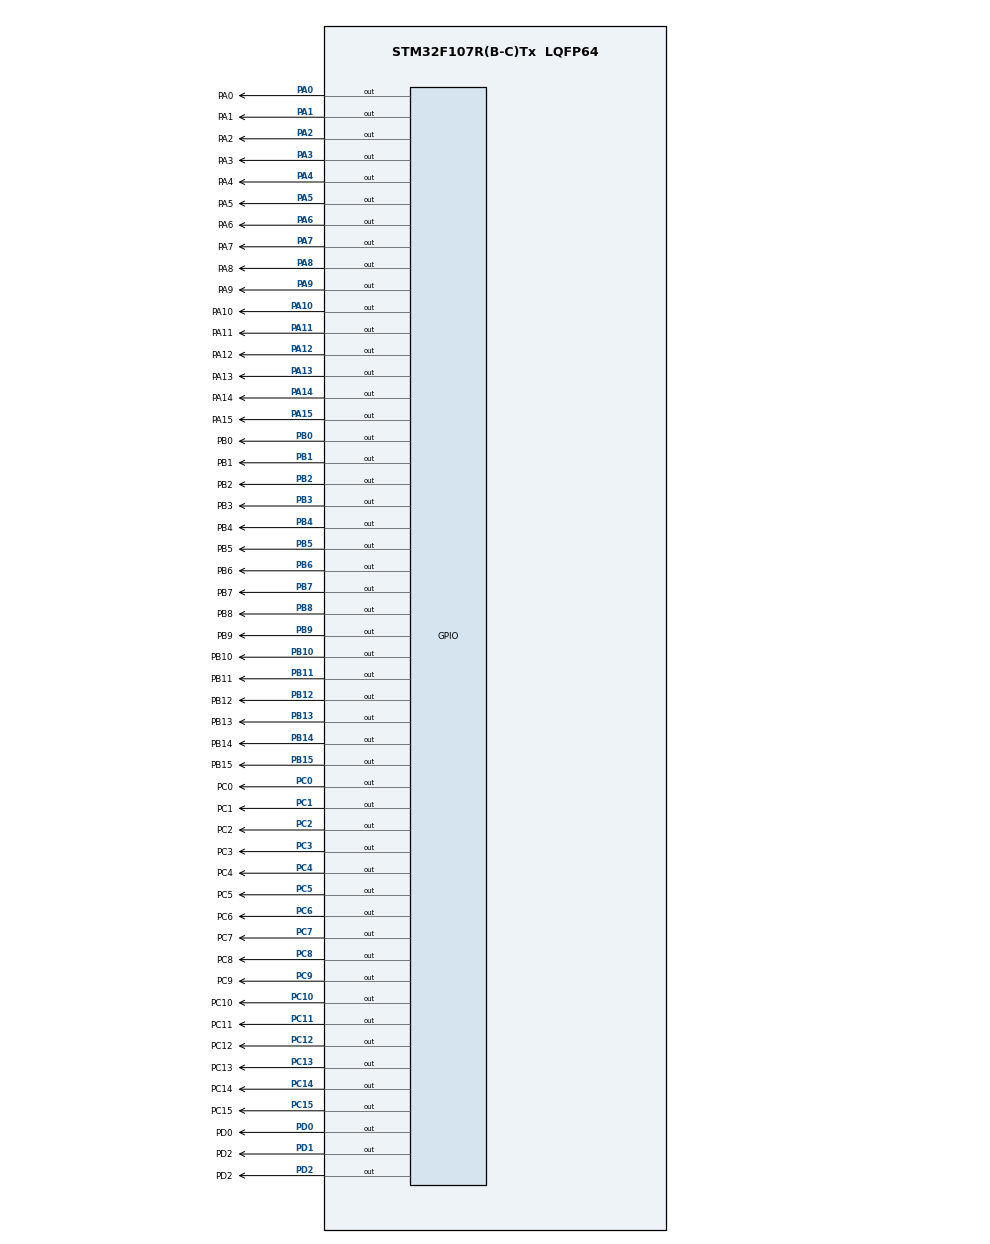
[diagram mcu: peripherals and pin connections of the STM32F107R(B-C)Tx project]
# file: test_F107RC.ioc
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Mcu.Family=STM32F1
PC10.Signal=GPIO_Output
PC12.Signal=GPIO_Output
PB14.GPIO_Label=PB14
PA14.GPIO_Label=PA14
PC0.GPIO_Label=PC0
PC6.GPIO_Label=PC6
PA6.GPIO_Label=PA6
PB0.GPIO_Label=PB0
PB6.GPIO_Label=PB6
PB13.GPIO_Label=PB13
PB11.Signal=GPIO_Output
PB13.Signal=GPIO_Output
PB15.Signal=GPIO_Output
PC15-OSC32_OUT.GPIO_Label=PC15
ProjectManager.StackSize=0x400
PD1-OSC_OUT.Signal=GPIO_Output
PA15.GPIO_Label=PA15
PD1-OSC_OUT.GPIO_Label=PD2
PA12.Signal=GPIO_Output
PB6.Signal=GPIO_Output
PC7.Signal=GPIO_Output
PC3.Signal=GPIO_Output
RCC.MSICalibrationValue=0
PB2.Signal=GPIO_Output
PB12.GPIO_Label=PB12
PC4.GPIO_Label=PC4
PB1.GPIO_Label=PB1
PC11.GPIO_Label=PC11
PA10.GPIO_Label=PA10
PB7.Signal=GPIO_Output
PA8.Signal=GPIO_Output
PB7.GPIO_Label=PB7
Mcu.Package=LQFP64
PB9.Signal=GPIO_Output
PB1.Signal=GPIO_Output
PA6.Signal=GPIO_Output
PA2.GPIO_Label=PA2
PA10.Signal=GPIO_Output
PA15.Signal=GPIO_Output
PB5.GPIO_Label=PB5
PC14-OSC32_IN.GPIO_Label=PC14
PC5.Signal=GPIO_Output
RCC.MSIAutoCalibration=DISABLED
PA4.GPIO_Label=PA4
PC2.GPIO_Label=PC2
PB4.Signal=GPIO_Output
PA3.Signal=GPIO_Output
PB3.GPIO_Label=PB3
PB9.GPIO_Label=PB9
PC10.GPIO_Label=PC10
PC9.GPIO_Label=PC9
PA9.GPIO_Label=PA9
PC11.Signal=GPIO_Output
PC8.Signal=GPIO_Output
PC2.Signal=GPIO_Output
PC4.Signal=GPIO_Output
PC6.Signal=GPIO_Output
PB11.GPIO_Label=PB11
PC13-TAMPER-RTC.Signal=GPIO_Output
PA11.GPIO_Label=PA11
PD0-OSC_IN.Signal=GPIO_Output
PC0.Signal=GPIO_Output
PC14-OSC32_IN.Signal=GPIO_Output
VP_SYS_VS_ND.Mode=No_Debug
PA12.GPIO_Label=PA12
RCC.PWR_Regulator_Voltage_Scale=PWR_REGULATOR_VOLTAGE_SCALE1
PA0-WKUP.GPIO_Label=PA0
PA0-WKUP.Signal=GPIO_Output
PC8.GPIO_Label=PC8
PA13.Signal=GPIO_Output
PB8.GPIO_Label=PB8
PA8.GPIO_Label=PA8
ProjectManager.TargetToolchain=STM32CubeIDE
PB10.GPIO_Label=PB10
PA9.Signal=GPIO_Output
RCC.USBFreq_Value=10666666.666666666
PC15-OSC32_OUT.Signal=GPIO_Output
PA1.Signal=GPIO_Output
PB10.Signal=GPIO_Output
PB14.Signal=GPIO_Output
PA5.Signal=GPIO_Output
board=custom
PD0-OSC_IN.GPIO_Label=PD0
PC13-TAMPER-RTC.GPIO_Label=PC13
PB4.GPIO_Label=PB4
PB15.GPIO_Label=PB15
PA1.GPIO_Label=PA1
PC1.GPIO_Label=PC1
Mcu.Name=STM32F107R(B-C)Tx
PA2.Signal=GPIO_Output
PA13.GPIO_Label=PA13
PC7.GPIO_Label=PC7
PB3.Signal=GPIO_Output
PA4.Signal=GPIO_Output
PB5.Signal=GPIO_Output
PA7.GPIO_Label=PA7
PA5.GPIO_Label=PA5
PC5.GPIO_Label=PC5
PC12.GPIO_Label=PC12
PA11.Signal=GPIO_Output
PA14.Signal=GPIO_Output
PB2.GPIO_Label=PB2
ProjectManager.HeapSize=0x200
NVIC.PriorityGroup=NVIC_PRIORITYGROUP_4
PB8.Signal=GPIO_Output
PC3.GPIO_Label=PC3
PC9.Signal=GPIO_Output
PD2.Signal=GPIO_Output
PB0.Signal=GPIO_Output
PC1.Signal=GPIO_Output
PB12.Signal=GPIO_Output
PD2.GPIO_Label=PD2
PA3.GPIO_Label=PA3
PA7.Signal=GPIO_Output

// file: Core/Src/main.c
/* USER CODE BEGIN Header */
/**
  ******************************************************************************
  * @file           : main.c
  * @brief          : Main program body
  ******************************************************************************
  * @attention
  *
  * <h2><center>&copy; Copyright (c) 2021 STMicroelectronics.
  * All rights reserved.</center></h2>
  *
  * This software component is licensed by ST under BSD 3-Clause license,
  * the "License"; You may not use this file except in compliance with the
  * License. You may obtain a copy of the License at:
  *                        opensource.org/licenses/BSD-3-Clause
  *
  ******************************************************************************
  */
/* USER CODE END Header */
#include "main.h"

/* USER CODE BEGIN Includes */
#include "gpio_ex.h"
/* USER CODE END Includes */

void SystemClock_Config(void);
static void MX_GPIO_Init(void);

int main(void)
{

  /* MCU Configuration--------------------------------------------------------*/

  /* Reset of all peripherals, Initializes the Flash interface and the Systick. */
  HAL_Init();

  /* Configure the system clock */
  SystemClock_Config();

  /* Initialize all configured peripherals */
  MX_GPIO_Init();

  /* Infinite loop */
  /* USER CODE BEGIN WHILE */
  uint16_t i = 0;
  while (1) {
    /* USER CODE END WHILE */
    HAL_GPIO_SetWord(GPIOA, i);
    HAL_GPIO_SetWord(GPIOB, i);
    HAL_GPIO_SetWord(GPIOC, i);
    HAL_GPIO_SetWord(GPIOD, i & 0x07);
    ++i;
  }
}

void SystemClock_Config(void)
{
  RCC_OscInitTypeDef RCC_OscInitStruct = {0};
  RCC_ClkInitTypeDef RCC_ClkInitStruct = {0};

  /** Initializes the RCC Oscillators according to the specified parameters
  * in the RCC_OscInitTypeDef structure.
  */
  RCC_OscInitStruct.OscillatorType = RCC_OSCILLATORTYPE_HSI;
  RCC_OscInitStruct.HSIState = RCC_HSI_ON;
  RCC_OscInitStruct.HSICalibrationValue = RCC_HSICALIBRATION_DEFAULT;
  RCC_OscInitStruct.PLL.PLLState = RCC_PLL_NONE;
  RCC_OscInitStruct.PLL2.PLL2State = RCC_PLL_NONE;
  if (HAL_RCC_OscConfig(&RCC_OscInitStruct) != HAL_OK)
  {
    Error_Handler();
  }
  /** Initializes the CPU, AHB and APB buses clocks
  */
  RCC_ClkInitStruct.ClockType = RCC_CLOCKTYPE_HCLK|RCC_CLOCKTYPE_SYSCLK
                              |RCC_CLOCKTYPE_PCLK1|RCC_CLOCKTYPE_PCLK2;
  RCC_ClkInitStruct.SYSCLKSource = RCC_SYSCLKSOURCE_HSI;
  RCC_ClkInitStruct.AHBCLKDivider = RCC_SYSCLK_DIV1;
  RCC_ClkInitStruct.APB1CLKDivider = RCC_HCLK_DIV1;
  RCC_ClkInitStruct.APB2CLKDivider = RCC_HCLK_DIV1;

  if (HAL_RCC_ClockConfig(&RCC_ClkInitStruct, FLASH_LATENCY_0) != HAL_OK)
  {
    Error_Handler();
  }
  /** Configure the Systick interrupt time
  */
  __HAL_RCC_PLLI2S_ENABLE();
}

static void MX_GPIO_Init(void)
{
  GPIO_InitTypeDef GPIO_InitStruct = {0};

  /* GPIO Ports Clock Enable */
  __HAL_RCC_GPIOC_CLK_ENABLE();
  __HAL_RCC_GPIOD_CLK_ENABLE();
  __HAL_RCC_GPIOA_CLK_ENABLE();
  __HAL_RCC_GPIOB_CLK_ENABLE();

  /*Configure GPIO pin Output Level */
  HAL_GPIO_WritePin(GPIOC, PC13_Pin|PC14_Pin|PC15_Pin|PC0_Pin
                          |PC1_Pin|PC2_Pin|PC3_Pin|PC4_Pin
                          |PC5_Pin|PC6_Pin|PC7_Pin|PC8_Pin
                          |PC9_Pin|PC10_Pin|PC11_Pin|PC12_Pin, GPIO_PIN_RESET);

  /*Configure GPIO pin Output Level */
  HAL_GPIO_WritePin(GPIOD, PD0_Pin|PD2_Pin|PD2D2_Pin, GPIO_PIN_RESET);

  /*Configure GPIO pin Output Level */
  HAL_GPIO_WritePin(GPIOA, PA0_Pin|PA1_Pin|PA2_Pin|PA3_Pin
                          |PA4_Pin|PA5_Pin|PA6_Pin|PA7_Pin
                          |PA8_Pin|PA9_Pin|PA10_Pin|PA11_Pin
                          |PA12_Pin|PA13_Pin|PA14_Pin|PA15_Pin, GPIO_PIN_RESET);

  /*Configure GPIO pin Output Level */
  HAL_GPIO_WritePin(GPIOB, PB0_Pin|PB1_Pin|PB2_Pin|PB10_Pin
                          |PB11_Pin|PB12_Pin|PB13_Pin|PB14_Pin
                          |PB15_Pin|PB3_Pin|PB4_Pin|PB5_Pin
                          |PB6_Pin|PB7_Pin|PB8_Pin|PB9_Pin, GPIO_PIN_RESET);

  /*Configure GPIO pins : PC13_Pin PC14_Pin PC15_Pin PC0_Pin
                           PC1_Pin PC2_Pin PC3_Pin PC4_Pin
                           PC5_Pin PC6_Pin PC7_Pin PC8_Pin
                           PC9_Pin PC10_Pin PC11_Pin PC12_Pin */
  GPIO_InitStruct.Pin = PC13_Pin|PC14_Pin|PC15_Pin|PC0_Pin
                          |PC1_Pin|PC2_Pin|PC3_Pin|PC4_Pin
                          |PC5_Pin|PC6_Pin|PC7_Pin|PC8_Pin
                          |PC9_Pin|PC10_Pin|PC11_Pin|PC12_Pin;
  GPIO_InitStruct.Mode = GPIO_MODE_OUTPUT_PP;
  GPIO_InitStruct.Pull = GPIO_NOPULL;
  GPIO_InitStruct.Speed = GPIO_SPEED_FREQ_LOW;
  HAL_GPIO_Init(GPIOC, &GPIO_InitStruct);

  /*Configure GPIO pins : PD0_Pin PD2_Pin PD2D2_Pin */
  GPIO_InitStruct.Pin = PD0_Pin|PD2_Pin|PD2D2_Pin;
  GPIO_InitStruct.Mode = GPIO_MODE_OUTPUT_PP;
  GPIO_InitStruct.Pull = GPIO_NOPULL;
  GPIO_InitStruct.Speed = GPIO_SPEED_FREQ_LOW;
  HAL_GPIO_Init(GPIOD, &GPIO_InitStruct);

  /*Configure GPIO pins : PA0_Pin PA1_Pin PA2_Pin PA3_Pin
                           PA4_Pin PA5_Pin PA6_Pin PA7_Pin
                           PA8_Pin PA9_Pin PA10_Pin PA11_Pin
                           PA12_Pin PA13_Pin PA14_Pin PA15_Pin */
  GPIO_InitStruct.Pin = PA0_Pin|PA1_Pin|PA2_Pin|PA3_Pin
                          |PA4_Pin|PA5_Pin|PA6_Pin|PA7_Pin
                          |PA8_Pin|PA9_Pin|PA10_Pin|PA11_Pin
                          |PA12_Pin|PA13_Pin|PA14_Pin|PA15_Pin;
  GPIO_InitStruct.Mode = GPIO_MODE_OUTPUT_PP;
  GPIO_InitStruct.Pull = GPIO_NOPULL;
  GPIO_InitStruct.Speed = GPIO_SPEED_FREQ_LOW;
  HAL_GPIO_Init(GPIOA, &GPIO_InitStruct);

  /*Configure GPIO pins : PB0_Pin PB1_Pin PB2_Pin PB10_Pin
                           PB11_Pin PB12_Pin PB13_Pin PB14_Pin
                           PB15_Pin PB3_Pin PB4_Pin PB5_Pin
                           PB6_Pin PB7_Pin PB8_Pin PB9_Pin */
  GPIO_InitStruct.Pin = PB0_Pin|PB1_Pin|PB2_Pin|PB10_Pin
                          |PB11_Pin|PB12_Pin|PB13_Pin|PB14_Pin
                          |PB15_Pin|PB3_Pin|PB4_Pin|PB5_Pin
                          |PB6_Pin|PB7_Pin|PB8_Pin|PB9_Pin;
  GPIO_InitStruct.Mode = GPIO_MODE_OUTPUT_PP;
  GPIO_InitStruct.Pull = GPIO_NOPULL;
  GPIO_InitStruct.Speed = GPIO_SPEED_FREQ_LOW;
  HAL_GPIO_Init(GPIOB, &GPIO_InitStruct);

  /*Configure peripheral I/O remapping */
  __HAL_AFIO_REMAP_PD01_ENABLE();

}

void Error_Handler(void)
{
  __disable_irq();
  while (1)
  {
  }
}

/************************ (C) COPYRIGHT STMicroelectronics *****END OF FILE****/
